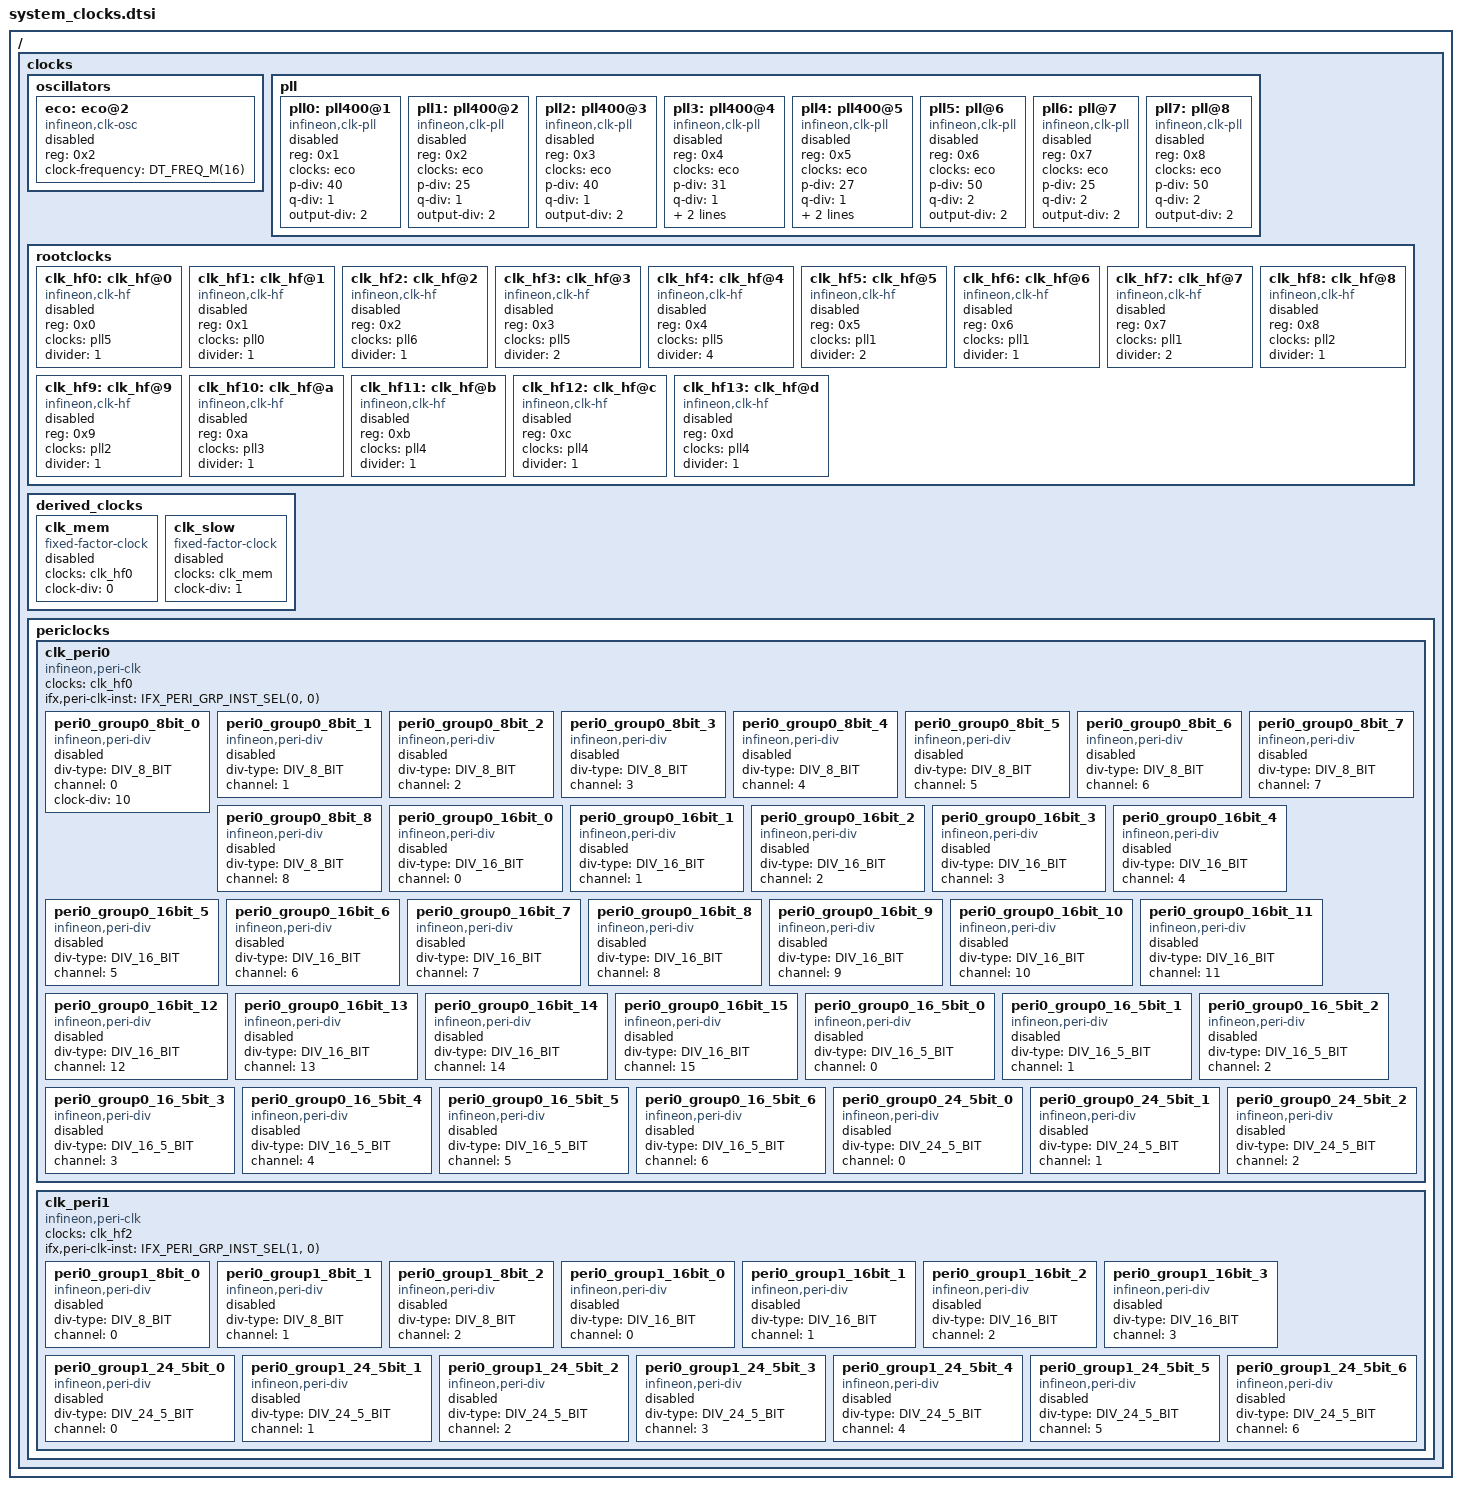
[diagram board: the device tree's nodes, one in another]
/*
 * SPDX-FileCopyrightText: Copyright (c) 2026 Linumiz
 * SPDX-FileCopyrightText: Copyright (c) 2026 Infineon Technologies AG,
 * SPDX-FileCopyrightText: or an affiliate of Infineon Technologies AG. All rights reserved.
 *
 * SPDX-License-Identifier: Apache-2.0
 */

#define DIV_8_BIT    00
#define DIV_16_BIT   01
#define DIV_16_5_BIT 02
#define DIV_24_5_BIT 03

#define IFX_PERI_GRP_INST_SEL(grpnum, instnum) ((grpnum << 8U) | (instnum << 16U))

#include <freq.h>
#include <zephyr/dt-bindings/pinctrl/ifx_cat1-pinctrl.h>

/ {
	clocks: clocks {
		oscillators: oscillators {
			#address-cells = <1>;
			#size-cells = <0>;

			eco: eco@2 {
				compatible = "infineon,clk-osc";
				reg = <0x2>;
				#clock-cells = <0>;
				clock-frequency = <DT_FREQ_M(16)>;
				status = "disabled";
			};
		};

		pll {
			#address-cells = <1>;
			#size-cells = <0>;

			pll0: pll400@1 {
				compatible = "infineon,clk-pll";
				reg = <0x1>;
				#clock-cells = <0>;
				clocks = <&eco>;
				p-div = <40>;
				q-div = <1>;
				output-div = <2>;
				status = "disabled";
			};

			pll1: pll400@2 {
				compatible = "infineon,clk-pll";
				reg = <0x2>;
				#clock-cells = <0>;
				clocks = <&eco>;
				p-div = <25>;
				q-div = <1>;
				output-div = <2>;
				status = "disabled";
			};

			pll2: pll400@3 {
				compatible = "infineon,clk-pll";
				reg = <0x3>;
				#clock-cells = <0>;
				clocks = <&eco>;
				p-div = <40>;
				q-div = <1>;
				output-div = <2>;
				status = "disabled";
			};

			pll3: pll400@4 {
				compatible = "infineon,clk-pll";
				reg = <0x4>;
				#clock-cells = <0>;
				clocks = <&eco>;
				p-div = <31>;
				q-div = <1>;
				frac-div = <0x400000>;
				output-div = <2>;
				status = "disabled";
			};

			pll4: pll400@5 {
				compatible = "infineon,clk-pll";
				reg = <0x5>;
				#clock-cells = <0>;
				clocks = <&eco>;
				p-div = <27>;
				q-div = <1>;
				output-div = <2>;
				frac-div = <0x800000>;
				status = "disabled";
			};

			pll5: pll@6 {
				compatible = "infineon,clk-pll";
				reg = <0x6>;
				#clock-cells = <0>;
				clocks = <&eco>;
				p-div = <50>;
				q-div = <2>;
				output-div = <2>;
				status = "disabled";
			};

			pll6: pll@7 {
				compatible = "infineon,clk-pll";
				reg = <0x7>;
				#clock-cells = <0>;
				clocks = <&eco>;
				p-div = <25>;
				q-div = <2>;
				output-div = <2>;
				status = "disabled";
			};

			pll7: pll@8 {
				compatible = "infineon,clk-pll";
				reg = <0x8>;
				#clock-cells = <0>;
				clocks = <&eco>;
				p-div = <50>;
				q-div = <2>;
				output-div = <2>;
				status = "disabled";
			};
		};

		rootclocks {
			#address-cells = <1>;
			#size-cells = <0>;

			clk_hf0: clk_hf@0 {
				compatible = "infineon,clk-hf";
				reg = <0x0>;
				#clock-cells = <0>;
				clocks = <&pll5>;
				divider = <1>;
				status = "disabled";
			};

			clk_hf1: clk_hf@1 {
				compatible = "infineon,clk-hf";
				reg = <0x1>;
				#clock-cells = <0>;
				clocks = <&pll0>;
				divider = <1>;
				status = "disabled";
			};

			clk_hf2: clk_hf@2 {
				compatible = "infineon,clk-hf";
				reg = <0x2>;
				#clock-cells = <0>;
				clocks = <&pll6>;
				divider = <1>;
				status = "disabled";
			};

			clk_hf3: clk_hf@3 {
				compatible = "infineon,clk-hf";
				reg = <0x3>;
				#clock-cells = <0>;
				clocks = <&pll5>;
				divider = <2>;
				status = "disabled";
			};

			clk_hf4: clk_hf@4 {
				compatible = "infineon,clk-hf";
				reg = <0x4>;
				#clock-cells = <0>;
				clocks = <&pll5>;
				divider = <4>;
				status = "disabled";
			};

			clk_hf5: clk_hf@5 {
				compatible = "infineon,clk-hf";
				reg = <0x5>;
				#clock-cells = <0>;
				clocks = <&pll1>;
				divider = <2>;
				status = "disabled";
			};

			clk_hf6: clk_hf@6 {
				compatible = "infineon,clk-hf";
				reg = <0x6>;
				#clock-cells = <0>;
				clocks = <&pll1>;
				divider = <1>;
				status = "disabled";
			};

			clk_hf7: clk_hf@7 {
				compatible = "infineon,clk-hf";
				reg = <0x7>;
				#clock-cells = <0>;
				clocks = <&pll1>;
				divider = <2>;
				status = "disabled";
			};

			clk_hf8: clk_hf@8 {
				compatible = "infineon,clk-hf";
				reg = <0x8>;
				#clock-cells = <0>;
				clocks = <&pll2>;
				divider = <1>;
				status = "disabled";
			};

			clk_hf9: clk_hf@9 {
				compatible = "infineon,clk-hf";
				reg = <0x9>;
				#clock-cells = <0>;
				clocks = <&pll2>;
				divider = <1>;
				status = "disabled";
			};

			clk_hf10: clk_hf@a {
				compatible = "infineon,clk-hf";
				reg = <0xa>;
				#clock-cells = <0>;
				clocks = <&pll3>;
				divider = <1>;
				status = "disabled";
			};

			clk_hf11: clk_hf@b {
				compatible = "infineon,clk-hf";
				reg = <0xb>;
				#clock-cells = <0>;
				clocks = <&pll4>;
				divider = <1>;
				status = "disabled";
			};

			clk_hf12: clk_hf@c {
				compatible = "infineon,clk-hf";
				reg = <0xc>;
				#clock-cells = <0>;
				clocks = <&pll4>;
				divider = <1>;
				status = "disabled";
			};

			clk_hf13: clk_hf@d {
				compatible = "infineon,clk-hf";
				reg = <0xd>;
				#clock-cells = <0>;
				clocks = <&pll4>;
				divider = <1>;
				status = "disabled";
			};
		};

		derived_clocks {
			clk_mem: clk_mem {
				compatible = "fixed-factor-clock";
				clocks = <&clk_hf0>;
				#clock-cells = <0>;
				clock-div = <0>;
				status = "disabled";
			};

			clk_slow: clk_slow {
				compatible = "fixed-factor-clock";
				clocks = <&clk_mem>;
				#clock-cells = <0>;
				clock-div = <1>;
				status = "disabled";
			};
		};

		periclocks {
			clk_peri0: clk_peri0 {
				compatible = "infineon,peri-clk";
				clocks = <&clk_hf0>;
				ifx,peri-clk-inst = <IFX_PERI_GRP_INST_SEL(0, 0)>;

				peri0_group0_8bit_0: peri0_group0_8bit_0 {
					compatible = "infineon,peri-div";
					#clock-cells = <0>;
					div-type = <DIV_8_BIT>;
					channel = <0>;
					clock-div = <10>;
					status = "disabled";
				};

				peri0_group0_8bit_1: peri0_group0_8bit_1 {
					compatible = "infineon,peri-div";
					#clock-cells = <0>;
					div-type = <DIV_8_BIT>;
					channel = <1>;
					status = "disabled";
				};

				peri0_group0_8bit_2: peri0_group0_8bit_2 {
					compatible = "infineon,peri-div";
					#clock-cells = <0>;
					div-type = <DIV_8_BIT>;
					channel = <2>;
					status = "disabled";
				};

				peri0_group0_8bit_3: peri0_group0_8bit_3 {
					compatible = "infineon,peri-div";
					#clock-cells = <0>;
					div-type = <DIV_8_BIT>;
					channel = <3>;
					status = "disabled";
				};

				peri0_group0_8bit_4: peri0_group0_8bit_4 {
					compatible = "infineon,peri-div";
					#clock-cells = <0>;
					div-type = <DIV_8_BIT>;
					channel = <4>;
					status = "disabled";
				};

				peri0_group0_8bit_5: peri0_group0_8bit_5 {
					compatible = "infineon,peri-div";
					#clock-cells = <0>;
					div-type = <DIV_8_BIT>;
					channel = <5>;
					status = "disabled";
				};

				peri0_group0_8bit_6: peri0_group0_8bit_6 {
					compatible = "infineon,peri-div";
					#clock-cells = <0>;
					div-type = <DIV_8_BIT>;
					channel = <6>;
					status = "disabled";
				};

				peri0_group0_8bit_7: peri0_group0_8bit_7 {
					compatible = "infineon,peri-div";
					#clock-cells = <0>;
					div-type = <DIV_8_BIT>;
					channel = <7>;
					status = "disabled";
				};

				peri0_group0_8bit_8: peri0_group0_8bit_8 {
					compatible = "infineon,peri-div";
					#clock-cells = <0>;
					div-type = <DIV_8_BIT>;
					channel = <8>;
					status = "disabled";
				};

				peri0_group0_16bit_0: peri0_group0_16bit_0 {
					compatible = "infineon,peri-div";
					#clock-cells = <0>;
					div-type = <DIV_16_BIT>;
					channel = <0>;
					status = "disabled";
				};

				peri0_group0_16bit_1: peri0_group0_16bit_1 {
					compatible = "infineon,peri-div";
					#clock-cells = <0>;
					div-type = <DIV_16_BIT>;
					channel = <1>;
					status = "disabled";
				};

				peri0_group0_16bit_2: peri0_group0_16bit_2 {
					compatible = "infineon,peri-div";
					#clock-cells = <0>;
					div-type = <DIV_16_BIT>;
					channel = <2>;
					status = "disabled";
				};

				peri0_group0_16bit_3: peri0_group0_16bit_3 {
					compatible = "infineon,peri-div";
					#clock-cells = <0>;
					div-type = <DIV_16_BIT>;
					channel = <3>;
					status = "disabled";
				};

				peri0_group0_16bit_4: peri0_group0_16bit_4 {
					compatible = "infineon,peri-div";
					#clock-cells = <0>;
					div-type = <DIV_16_BIT>;
					channel = <4>;
					status = "disabled";
				};

				peri0_group0_16bit_5: peri0_group0_16bit_5 {
					compatible = "infineon,peri-div";
					#clock-cells = <0>;
					div-type = <DIV_16_BIT>;
					channel = <5>;
					status = "disabled";
				};

				peri0_group0_16bit_6: peri0_group0_16bit_6 {
					compatible = "infineon,peri-div";
					#clock-cells = <0>;
					div-type = <DIV_16_BIT>;
					channel = <6>;
					status = "disabled";
				};

				peri0_group0_16bit_7: peri0_group0_16bit_7 {
					compatible = "infineon,peri-div";
					#clock-cells = <0>;
					div-type = <DIV_16_BIT>;
					channel = <7>;
					status = "disabled";
				};

				peri0_group0_16bit_8: peri0_group0_16bit_8 {
					compatible = "infineon,peri-div";
					#clock-cells = <0>;
					div-type = <DIV_16_BIT>;
					channel = <8>;
					status = "disabled";
				};

				peri0_group0_16bit_9: peri0_group0_16bit_9 {
					compatible = "infineon,peri-div";
					#clock-cells = <0>;
					div-type = <DIV_16_BIT>;
					channel = <9>;
					status = "disabled";
				};

				peri0_group0_16bit_10: peri0_group0_16bit_10 {
					compatible = "infineon,peri-div";
					#clock-cells = <0>;
					div-type = <DIV_16_BIT>;
					channel = <10>;
					status = "disabled";
				};

				peri0_group0_16bit_11: peri0_group0_16bit_11 {
					compatible = "infineon,peri-div";
					#clock-cells = <0>;
					div-type = <DIV_16_BIT>;
					channel = <11>;
					status = "disabled";
				};

				peri0_group0_16bit_12: peri0_group0_16bit_12 {
					compatible = "infineon,peri-div";
					#clock-cells = <0>;
					div-type = <DIV_16_BIT>;
					channel = <12>;
					status = "disabled";
				};

				peri0_group0_16bit_13: peri0_group0_16bit_13 {
					compatible = "infineon,peri-div";
					#clock-cells = <0>;
					div-type = <DIV_16_BIT>;
					channel = <13>;
					status = "disabled";
				};

				peri0_group0_16bit_14: peri0_group0_16bit_14 {
					compatible = "infineon,peri-div";
					#clock-cells = <0>;
					div-type = <DIV_16_BIT>;
					channel = <14>;
					status = "disabled";
				};

				peri0_group0_16bit_15: peri0_group0_16bit_15 {
					compatible = "infineon,peri-div";
					#clock-cells = <0>;
					div-type = <DIV_16_BIT>;
					channel = <15>;
					status = "disabled";
				};

				peri0_group0_16_5bit_0: peri0_group0_16_5bit_0 {
					compatible = "infineon,peri-div";
					#clock-cells = <0>;
					div-type = <DIV_16_5_BIT>;
					channel = <0>;
					status = "disabled";
				};

				peri0_group0_16_5bit_1: peri0_group0_16_5bit_1 {
					compatible = "infineon,peri-div";
					#clock-cells = <0>;
					div-type = <DIV_16_5_BIT>;
					channel = <1>;
					status = "disabled";
				};

				peri0_group0_16_5bit_2: peri0_group0_16_5bit_2 {
					compatible = "infineon,peri-div";
					#clock-cells = <0>;
					div-type = <DIV_16_5_BIT>;
					channel = <2>;
					status = "disabled";
				};

				peri0_group0_16_5bit_3: peri0_group0_16_5bit_3 {
					compatible = "infineon,peri-div";
					#clock-cells = <0>;
					div-type = <DIV_16_5_BIT>;
					channel = <3>;
					status = "disabled";
				};

				peri0_group0_16_5bit_4: peri0_group0_16_5bit_4 {
					compatible = "infineon,peri-div";
					#clock-cells = <0>;
					div-type = <DIV_16_5_BIT>;
					channel = <4>;
					status = "disabled";
				};

				peri0_group0_16_5bit_5: peri0_group0_16_5bit_5 {
					compatible = "infineon,peri-div";
					#clock-cells = <0>;
					div-type = <DIV_16_5_BIT>;
					channel = <5>;
					status = "disabled";
				};

				peri0_group0_16_5bit_6: peri0_group0_16_5bit_6 {
					compatible = "infineon,peri-div";
					#clock-cells = <0>;
					div-type = <DIV_16_5_BIT>;
					channel = <6>;
					status = "disabled";
				};

				peri0_group0_24_5bit_0: peri0_group0_24_5bit_0 {
					compatible = "infineon,peri-div";
					#clock-cells = <0>;
					div-type = <DIV_24_5_BIT>;
					channel = <0>;
					status = "disabled";
				};

				peri0_group0_24_5bit_1: peri0_group0_24_5bit_1 {
					compatible = "infineon,peri-div";
					#clock-cells = <0>;
					div-type = <DIV_24_5_BIT>;
					channel = <1>;
					status = "disabled";
				};

				peri0_group0_24_5bit_2: peri0_group0_24_5bit_2 {
					compatible = "infineon,peri-div";
					#clock-cells = <0>;
					div-type = <DIV_24_5_BIT>;
					channel = <2>;
					status = "disabled";
				};
			};

			clk_peri1: clk_peri1 {
				compatible = "infineon,peri-clk";
				clocks = <&clk_hf2>;
				ifx,peri-clk-inst = <IFX_PERI_GRP_INST_SEL(1, 0)>;

				peri0_group1_8bit_0: peri0_group1_8bit_0 {
					compatible = "infineon,peri-div";
					#clock-cells = <0>;
					div-type = <DIV_8_BIT>;
					channel = <0>;
					status = "disabled";
				};

				peri0_group1_8bit_1: peri0_group1_8bit_1 {
					compatible = "infineon,peri-div";
					#clock-cells = <0>;
					div-type = <DIV_8_BIT>;
					channel = <1>;
					status = "disabled";
				};

				peri0_group1_8bit_2: peri0_group1_8bit_2 {
					compatible = "infineon,peri-div";
					#clock-cells = <0>;
					div-type = <DIV_8_BIT>;
					channel = <2>;
					status = "disabled";
				};

				peri0_group1_16bit_0: peri0_group1_16bit_0 {
					compatible = "infineon,peri-div";
					#clock-cells = <0>;
					div-type = <DIV_16_BIT>;
					channel = <0>;
					status = "disabled";
				};

				peri0_group1_16bit_1: peri0_group1_16bit_1 {
					compatible = "infineon,peri-div";
					#clock-cells = <0>;
					div-type = <DIV_16_BIT>;
					channel = <1>;
					status = "disabled";
				};

				peri0_group1_16bit_2: peri0_group1_16bit_2 {
					compatible = "infineon,peri-div";
					#clock-cells = <0>;
					div-type = <DIV_16_BIT>;
					channel = <2>;
					status = "disabled";
				};

				peri0_group1_16bit_3: peri0_group1_16bit_3 {
					compatible = "infineon,peri-div";
					#clock-cells = <0>;
					div-type = <DIV_16_BIT>;
					channel = <3>;
					status = "disabled";
				};

				peri0_group1_24_5bit_0: peri0_group1_24_5bit_0 {
					compatible = "infineon,peri-div";
					#clock-cells = <0>;
					div-type = <DIV_24_5_BIT>;
					channel = <0>;
					status = "disabled";
				};

				peri0_group1_24_5bit_1: peri0_group1_24_5bit_1 {
					compatible = "infineon,peri-div";
					#clock-cells = <0>;
					div-type = <DIV_24_5_BIT>;
					channel = <1>;
					status = "disabled";
				};

				peri0_group1_24_5bit_2: peri0_group1_24_5bit_2 {
					compatible = "infineon,peri-div";
					#clock-cells = <0>;
					div-type = <DIV_24_5_BIT>;
					channel = <2>;
					status = "disabled";
				};

				peri0_group1_24_5bit_3: peri0_group1_24_5bit_3 {
					compatible = "infineon,peri-div";
					#clock-cells = <0>;
					div-type = <DIV_24_5_BIT>;
					channel = <3>;
					status = "disabled";
				};

				peri0_group1_24_5bit_4: peri0_group1_24_5bit_4 {
					compatible = "infineon,peri-div";
					#clock-cells = <0>;
					div-type = <DIV_24_5_BIT>;
					channel = <4>;
					status = "disabled";
				};

				peri0_group1_24_5bit_5: peri0_group1_24_5bit_5 {
					compatible = "infineon,peri-div";
					#clock-cells = <0>;
					div-type = <DIV_24_5_BIT>;
					channel = <5>;
					status = "disabled";
				};

				peri0_group1_24_5bit_6: peri0_group1_24_5bit_6 {
					compatible = "infineon,peri-div";
					#clock-cells = <0>;
					div-type = <DIV_24_5_BIT>;
					channel = <6>;
					status = "disabled";
				};
			};
		};
	};
};
